# M3351 register map
File version: 1.0
Registers are 32-bit, read-write, reset 0x0 unless marked. A register's access mark holds for its fields unless they carry their own. Offsets are from the block's base; [hi:lo] are bit positions; {n}, {i} and the like mark numbered series; 'fields as' and 'values as' point back to an identical list.

## I3C0 (part 2 of 2) — I3C Register Map
Base 0x40086000
Same registers: I3C0_NS 0x50086000
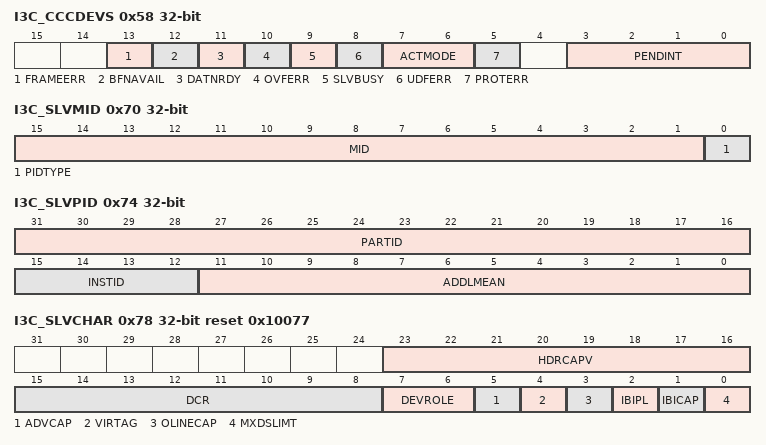
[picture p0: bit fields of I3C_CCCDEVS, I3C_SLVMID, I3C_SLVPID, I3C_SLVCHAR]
0x58 I3C_CCCDEVS ro — I3C Target Device Operating Status Register
  [13] FRAMEERR — Frame Error. This bit is set when private write request from Controller has frame error in HDR-DDR mode. Note: This bit is cleared only after Controller reads the device status through GETSTATUS CCC.
    0=Frame error did not occurred; 1=Frame error occurred
  [12] BFNAVAIL — Buffer Not Available. This bit is set when private write request from Controller is NACKED because of RX buffer not having RXSTATH (I3C_DBTHCTL[26:24]) number of empty locations or response buffer is full. Note: In SDR mode of operation, this bit is cleared when the Controller issues GETSTATUS CCC or upon space becoming available in the buffer and the successful completion of the next write transfer. Note: In HDR mode of operation, it is cleared only when Controller issues GETSTATUS CCC.
    0=Buffer Not Available did not occurred; 1=Buffer Not Available occurred
  [11] DATNRDY — Data Not Ready. This bit is set when private read request from Controller is NACKED because of any of the following conditions: Command FIFO Empty. Transmit FIFO threshold is not met. Response FIFO Full. Note: This bit is cleared when the Controller issues GETSTATUS CCC or upon successful completion of the subsequent read transfer.
    0=Data Not Ready did not occurred; 1=Data Not Ready occurred
  [10] OVFERR — Overflow Error. Overflow error condition detected during Controller write transfer. This bit is cleared only after Controller reads the device status through GETSTATUS CCC.
  [9] SLVBUSY — Target Busy. This bit is set if any change is made by the current Controller in to MRL register or occurance of any error. Note: This bit is cleared after Target application resumes the Target operation by writing RESUME bit (I3C_DEVCTL[30]) 1.
    0=Target not in Busy state; 1=Target in Busy state
  [8] UDFERR — Underflow Error. Underflow error condition detected during Controller read transfer. This bit is set if Target device terminates a read transfer because of unavailability of data in the transmit buffer. Note: This bit is cleared only after Controller reads the device status through GETSTATUS CCC.
    0=Underflow Error did not occurred; 1=Underflow Error occurred
  [7:6] ACTMODE — Activity Mode. This field is forced to be 0x0.
  [5] PROTERR — Protocol Error. This bit is set when the Target device encouters a Parity/CRC error during write data transfer. Note: This bit is cleared only after Controller reads the device status through GETSTATUS CCC.
    0=Protocol Error did not occurred; 1=Protocol Error occurred
  [3:0] PENDINT — Pending Interrupt. This field reflects the PENDINT (I3C_DEVCTL[6:3]) value.
0x70 I3C_SLVMID — I3C Target MIPI Manufacturer ID Register
  [15:1] MID — MIPI Manufacturer ID. This field reflects the PID[47:33]. (PID[47:0] Target Device 48-bit Provisioned ID)
  [0] PIDTYPE — Provisioned ID Type Selector. This bit reflects the PID[32]. (PID[47:0] Target Device 48-bit Provisioned ID)
    0=Vendor Fixed Value; 1=Random Value
0x74 I3C_SLVPID — I3C Target Provisional ID Register
  [31:16] PARTID — Part ID. This field reflects the PID[31:16]. (PID[47:0] Target Device 48-bit Provisioned ID)
  [15:12] INSTID — Instance ID. This field reflects the PID[15:12]. (PID[47:0] Target Device 48-bit Provisioned ID)
  [11:0] ADDLMEAN — Additional Meaning. This field reflects the PID[11:0]. (PID[47:0] Target Device 48-bit Provisioned ID)
0x78 I3C_SLVCHAR reset 0x10077 — I3C Target Characteristic Register
  [23:16] HDRCAPV — I3C Device HDR Capability Value. Forced to 0x1. Note: This field is read only.
  [15:8] DCR — I3C Device Characteristic Value. This field reflects the DCR[7:0] value.
  [7:6] DEVROLE — Device Role. This field reflects the BCR[7:6] and forced to 0x1. Note: This bit is read only.
  [5] ADVCAP — Advanced Capabilities. This bit reflects the BCR[5] value.
    0=Does not support optional advanced capabilities; 1=Supports optional advanced capabilities. Use GETCAPS CCC to determine which ones
  [4] VIRTAG — Virtual Target. This bit reflects the BCR[4] and forced to 0x1. Note: This bit is read only.
  [3] OLINECAP — Offline Capable. This bit reflects the BCR[3] and forced to 0x0. Note: This bit is read only.
  [2] IBIPL — IBI Payload. This bit reflects the BCR[2] and forced to 0x1. Note: This bit is read only.
  [1] IBICAP — IBI Request Capable. This bit reflects the BCR[1] and forced to 0x1. Note: This bit is read only.
  [0] MXDSLIMT — Max Data Speed Limitation. This bit reflects the BCR[0].
    0=No limitation; 1=Limitation
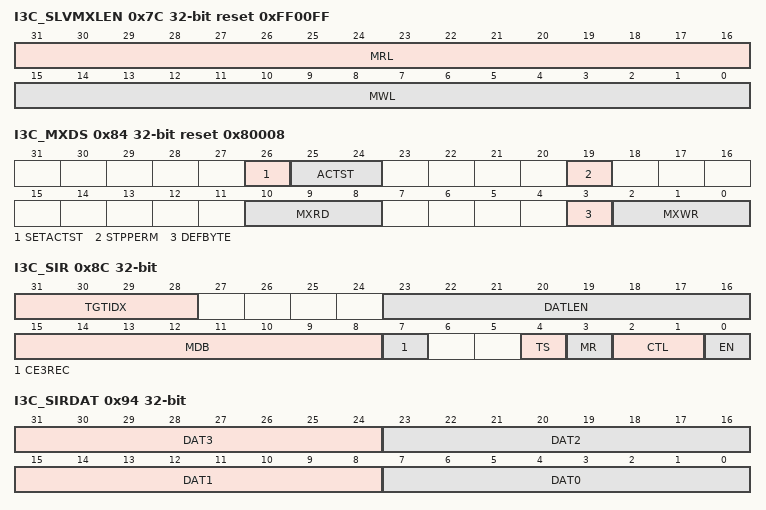
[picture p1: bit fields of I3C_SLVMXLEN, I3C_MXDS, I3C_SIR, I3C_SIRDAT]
0x7C I3C_SLVMXLEN ro reset 0xFF00FF — I3C Target Maximum Write/Read Length Register
  [31:16] MRL — I3C Device Max Read Length. This field reflects the maximum read length in Target mode. It only can be updated if SETMRL CCC is received. Note: This field is read only.
  [15:0] MWL — I3C Device Max Write Length. This field reflects the maximum write length in Target mode. It only can be updated if SETMWL CCC is received. Note: This field is read only.
0x84 I3C_MXDS reset 0x80008 — I3C Target Maximum Data Speed Register
  [26] SETACTST — Set Activity State. This bit indicates whether the Active Controller should set the Bus to the Activity State indicated in ACTST (I3C_MXDS[25:24]) before handing the Controller Role off to this I3C Device as part of the normal flow.
    0=The Target will not set the Bus to any Activity state; 1=The Target will set the Bus to any Activity state based on ACTST (I3C_MXDS[25:24])
  [25:24] ACTST — Active State. This 2-bit integer indicates whether this I3C device initially acts with a given Activity State, after becoming Active Controller on the Bus according to the Controller handoff flow.
  [19] STPPERM — Stop Permit. Specifies the STOP support between write and read.
    0=STOP after write will cancel the read; 1=Target permits the write and read to be seperated by a STOP
  [10:8] MXRD — Maximum Read Data Rate. Specifies the Maximum Sustained Data Rate for non-CCC messages sent by Target device to Controller device. Note: The 2nd byte which returned in the GETMXDS CCC.
  [3] DEFBYTE — Defining Byte support. Specifies the defining byte support of GETMXDS CCC.
    0=Defining byte is not supported for GETMXDS CCC; 1=Defining byte is supported for GETMXDS CCC
  [2:0] MXWR — Maximum Write Data Rate. Specifies the Maximum Sustained Data Rate for non-CCC messages sent by Controller device to Target device. Note: The 1st byte which returned in the GETMXDS CCC.
0x8C I3C_SIR — I3C Target Interrupt Request Control Register
  [31:28] TGTIDX — Target Index. This field should be programmed by the Target application to select from what Target the SIR is sent.
  [23:16] DATLEN — Target Interrupt Request Data Length. This field should be programmed by the Target application to give the data length for the payload data other than the MDB byte. This field is only applicable when BCR[2] (I3C_SLVCHAR[2] IBIPL) is set indicating that SIR supports payload data.
  [15:8] MDB — Mandatory Data Byte. This field gives the mandatory data byte which is required to be transmitted after the Controller ACK the Target address during SIR transfer. This field is only applicable when BCR[2] (I3C_SLVCHAR[2] IBIPL) is set indicating that SIR supports payload data.
  [7] CE3REC — CE3 Error Recovery. When the conditions for entering CE3 error are met (expiry of application running timer and I3C_SIR[0] (Target Interrupt Request) is not set to 0), the user will program this bit for recovering from CE3 error. Upon receiving this bit, the Target will move to Controller mode (update CTRACTS (I3C_PRESENTS[2] to 1) and generate a START (also clear the I3C_SIR[0]) and continue in generating 7E followed by STOP. Note: This bit is auto cleared by the Controller after the completion of recovery and moved to Controller mode.
    0=No effect; 1=Recovery from CE3 error
  [4] TS — Asynchronous Mode-0 Time Stamp. Enabling this bit will allow the Target to capture the Time-Stamp from external input signal during T_C1 (Target triggers START condition) and T_C2 (IBI is ACK by Controller) markers and append it along with the payload data.
    0=Time-Stamp payload data Disabled; 1=Time-Stamp payload data Enabled
  [3] MR — Controller Request. This bit is available only in the I3C Secondary Controller Configuration, and used for the Secondary Controller requests to be an Active Controller. Once issued and when the current Controller accepts (ACK) or if the Controller is unable to issue the MR, then the Controller clears this bit automatically and updates the IBISTS (I3C_SIRRESP[2:0]) field. If NACK response is received for the MR, the Controller reattempts the MR upon detecting the next START condition from the Controller or after the Bus Available Time.
    0=No effect; 1=Secondary Controller issues the MR on the I3C bus
  [2:1] CTL — Target Interrupt Request Control
    0=Indicates source of SIR data to be from the I3C_SIRDAT register; 1=Pull SDA line low and release SDA after sampling SCL low (pulled by Controller). Used for CE3 recovery during Controller Handover procedure
  [0] EN — Enable Target Interrupt Request. When set, the Target attempts to issue the SIR on the I3C bus based on CTL field. If CTL is set to 2'b00, Target clears this bit automatically and update the IBISTS field upon either current Controller accepts through generating (ACK) or If Target is unable to issue the SIR. If CTL is set to 2'b00, Target reattempts the SIR either upon detecting the next START condition from the Controller or after the Bus Available Time If NACK response is received for the SIR. If CTL is set to 2'b01, Target clears this bit automatically after sampling the SCL Low (pulled by Controller) for the generated SDA low. Target will release the SDA line upon sampling the SCL low. This feature is used in CE3 error recovery flow. Note: Once set, the application/software cannot clear this bit.
    0=No effect; 1=Send Target interrupt request
0x94 I3C_SIRDAT — I3C Target Interrupt Request Data Register
  [31:24] DAT3 — Data Byte 3. This register SIRDATA containing four bytes of SIR Data will be in effect only when SIR CTL (I3C_SIR[2:1]) is programmed to 0 provided the data length is up to 4. This field holds the fourth byte of SIR DATA that will be passed after the MDB when SIR is initiated by the application on writing into SIR EN (I3C_SIR[0]).
  [23:16] DAT2 — Data Byte 2. This register SIRDATA containing four bytes of SIR Data will be in effect only when SIR CTL (I3C_SIR[2:1]) is programmed to 0 provided the data length is up to 3. This field holds the third byte of SIR DATA that will be passed after the MDB when SIR is initiated by the application on writing into SIR EN (I3C_SIR[0]).
  [15:8] DAT1 — Data Byte 1. This register SIRDATA containing four bytes of SIR Data will be in effect only when SIR CTL (I3C_SIR[2:1]) is programmed to 0 provided the data length is up to 2. This field holds the second byte of SIR DATA that will be passed after the MDB when SIR is initiated by the application on writing into SIR EN (I3C_SIR[0]).
  [7:0] DAT0 — Data Byte 0. This register SIRDATA containing four bytes of SIR Data will be in effect only when SIR CTL (I3C_SIR[2:1]) is programmed to 0 provided the data length is up to 1. This field holds the first byte of SIR DATA that will be passed after the MDB when SIR is initiated by the application on writing into SIR EN (I3C_SIR[0]).
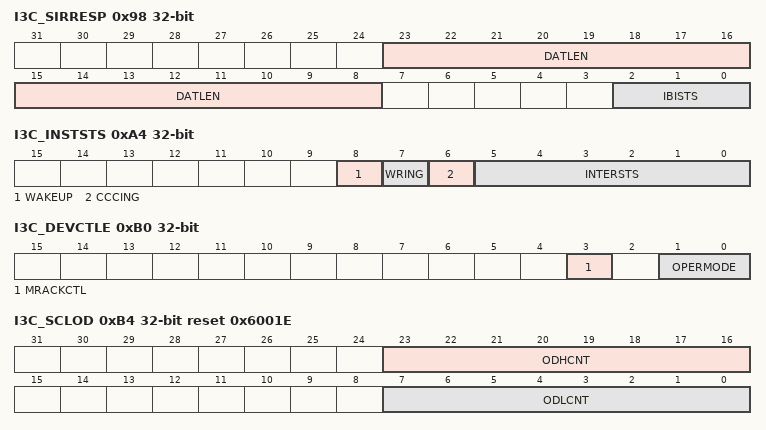
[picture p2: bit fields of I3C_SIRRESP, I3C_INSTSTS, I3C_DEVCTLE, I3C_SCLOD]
0x98 I3C_SIRRESP — I3C Target Interrupt Request Response Register
  [23:8] DATLEN — SIR Response Data Length. The value in this filed will indicate the number of bytes remaining that was not transmitted because of Controller early terminating the SIR transfer. In case the IBI is not attempted the number for bytes returned will be same as that programmed for IBI payload.
  [2:0] IBISTS — IBI Completion Status. This field is common for SIR and MR. Note: The Target does not attempt to issue the IBI and generates the IBI Completion Status as 3'b011 (IBI Not Attempted) if one of the following condition is true. The Controller has not assigned the Dynamic Address. The Controller has cleared the assigned Dynamic Address (through RSTDAA CCC). The Controller has disabled the IBI event (through DISEC CCC). The Controller has switched the role to Controller (applicable only for Secondary Controller Configuration). The Controller has NACKed the IBI request.
0xA4 I3C_INSTSTS ro — I3C Target Instant Status Register
  [8] WAKEUP — Target Wake-up Status. This bit indicates the Target is addressed and the application is required to be ready. Note 1: This bit is read only. Note 2: This bit is de-asserted after an address mismatch or on STOP. It is also de-asserted after a RE-START followed by 0x7E. This bit is synchronized from SCL domain to engine clock domain hence will have some synchronization latency associated with it.
    0=No address matched event; 1=An address match occurs indicating the Controller is trying to access this Target
  [7] WRING — Write Transfer On-going. This bit is asserted whenever there is an address match for the Controller Write transfer targeted for this Target. Note 1: This bit is read only. Note 2: This signal remains asserted until the write transfer is over from the Controller. This bit is synchronized from SCL domain to engine clock domain hence will have some synchronization latency associated with it.
    0=No write transfer operation; 1=Write transfer is on-going
  [6] CCCING — CCC Transfer On-going. Indicates a CCC transfer is on-going. This bit is asserted after 0x7E header the first bit of CCC is received and it is de-asserted either when a STOP or a 0x7E with a RE-START comes on the I3C line. Note 1: This bit is read only. Note 2: This bit is synchronized from SCL domain to engine clock domain hence will have some synchronization latency associated with it.
    0=No CCC transfer operation; 1=CCC transfer is on-going
  [5:0] INTERSTS — Target Internal Status. This field indicates the internal status of the Target. These bits indicates the internal status of the controller. Note: This field is read only.
0xB0 I3C_DEVCTLE — I3C Device Control Extended Register
  [3] MRACKCTL — ACK/NACK GETACCCR CCC. This bit is used in Target mode of operation. This bit serves as a Target (Secondare Controller) to ACK/NACK GETACCCR CCC from current Controller.
    0=ACK GETACCCR CCC; 1=NACK GETACCCR CCC
  [1:0] OPERMODE — Device Mode. This bit is used to select the Device Operation Mode before the device is enabled. Note 1: This field is written only when the I3C is disabled. Note 2: This field is automatically updated once the device role change happens in Secondary Controller mode.
    0=Controller; 1=Target
0xB4 I3C_SCLOD reset 0x6001E — I3C Controller Open Drain SCL Timing Register
  [23:16] ODHCNT — I3C Open Drain High Count. SCL Open-Drain High count for I3C transfers targeted to I3C Targets. Note: ODHCNT value can not be set 0 and minimum value is 5.
  [7:0] ODLCNT — I3C Open Drain Low Count. SCL Open-Drain Low count for I3C transfers targeted to I3C Targets. Note: ODLCNT value can not be set 0 and minimum value is 5.
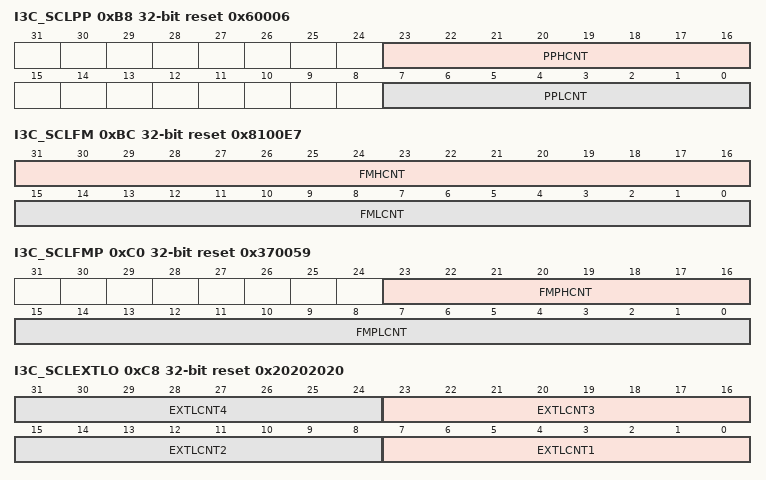
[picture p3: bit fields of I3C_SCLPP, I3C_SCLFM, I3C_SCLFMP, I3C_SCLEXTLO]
0xB8 I3C_SCLPP reset 0x60006 — I3C Controller Push Pull SCL Timing Register
  [23:16] PPHCNT — I3C Push Pull High Count. SCL Push-Pull High count for I3C transfers targeted to I3C Targets. Note: PPHCNT value can not be set 0 and minimum value is 5.
  [7:0] PPLCNT — I3C Push Pull Low Count. SCL Push-Pull Low count for I3C transfers targeted to I3C Targets. Note: PPLCNT value can not be set 0 and minimum value is 5.
0xBC I3C_SCLFM reset 0x8100E7 — I3C Controller I2C Fast Mode SCL Timing Register
  [31:16] FMHCNT — I2C Fast Mode High Count. SCL Open-Drain High count timing for I2C fast mode transfers. Note: FMHCNT value can not be set 0 and minimum value is 5.
  [15:0] FMLCNT — I2C Fast Mode Low Count. SCL Open-Drain Low count timing for I2C fast mode transfers. Note: FMLCNT value can not be set 0 and minimum value is 5.
0xC0 I3C_SCLFMP reset 0x370059 — I3C Controller I2C Fast Mode Plus SCL Timing Register
  [23:16] FMPHCNT — I2C Fast Mode Plus High Count. SCL Open-Drain High count timing for I2C fast mode plus transfers. Note: FMPHCNT value can not be set 0 and minimum value is 5.
  [15:0] FMPLCNT — I2C Fast Mode Plus Low Count. SCL Open-Drain Low count timing for I2C fast mode plus transfers. Note: FMPLCNT value can not be set 0 and minimum value is 5.
0xC8 I3C_SCLEXTLO reset 0x20202020 — I3C Controller SCL Extended Low Count Timing Register
  [8n-1:8n-8] EXTLCNT{n} (n=1..4) — I3C Extended Low Count {n}. This field is used for SDR{n} speed data transfer.
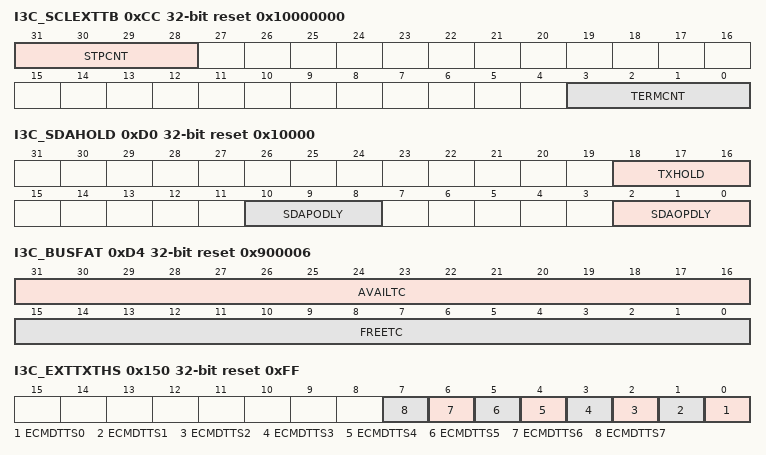
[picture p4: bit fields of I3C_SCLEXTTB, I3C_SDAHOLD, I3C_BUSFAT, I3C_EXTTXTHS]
0xCC I3C_SCLEXTTB reset 0x10000000 — I3C Controller SCL Extended Termination Bit Low Count Timing Register
  [31:28] STPCNT — STOP HOLD Count. Stop Hold Count in terms of ECLK which is used for generation of Stop Hold generation in Controller Mode.
  [3:0] TERMCNT — I3C Read Termination Bit Low Count. Extended I3C Read Termination Bit low count for I3C Read transfers. Effective Termination-Bit Low Period is derived based on the SDR speed mode as shown below: SDR0 speed: PPLCNT + TERMCNT. SDR1 speed: EXTLCNT1 + TERMCNT. SDR2 speed: EXTLCNT2 + TERMCNT. SDR3 speed: EXTLCNT3 + TERMCNT. SDR4 speed: EXTLCNT4 + TERMCNT. Note: The SDR0~4 speed mode is defined in SPEED field (Transfer Command Data Structure [23:21]).
0xD0 I3C_SDAHOLD reset 0x10000 — I3C Controller SDA Hold And Mode Switch Delay Timing Register
  [18:16] TXHOLD — Transmit Hold Time. This field is used to control the hold time of SDA during transmit mode in SDR DDR transfers. The valid values are 1 to 7. Others are Reserved. Note: Delay count unit is in terms of the core clock period.
  [10:8] SDAPODLY — SDA Push-Pull To Open-Drain Delay. The valid value are 0 to 4. Others are Reserved. Note: Delay count unit is in terms of the core clock period.
  [2:0] SDAOPDLY — SDA Open-Drain To Push-Pull Delay. The valid value are 0 to 4. Others are Reserved. Note: Delay count unit is in terms of the core clock period.
0xD4 I3C_BUSFAT reset 0x900006 — I3C Bus Free and Available Timing Register
  [31:16] AVAILTC — Target Bus Avaliable Time Count. This field is used in Target mode of operation. This field is used by the Target/Non-current Controller to initiate an IBI after STOP condition. Note: Bus Avaliable Time is used for issue In-Band Interrupt.
  [15:0] FREETC — Controller Bus Free Time Count. This field is used in Controller mode of operation. This field sets the Bus Free Time for initiating the transfer in Controller mode or generating IBI in non-current Controller mode. In Pure Bus System, this field represents tCAS parameter. In Mixed Bus system, this field is expected to be programmed to tLOW of I2C Timing.
0xD8 I3C_BUSIDLET reset 0x7080 — I3C Target Bus Idle Timing Register
  [19:0] IDLETC — Target Bus Idle Time Count. This field is used by the Target to initiate Hot-Join request if the Dynamic Address is not valid. Note: Bus Idle Time is used for issue Hot-Join request.
0xDC I3C_SCLLOWTO reset 0x3567E0 — I3C Controller SCL Low Timeout Register
  [25:0] LOWCNT — SCL Low Timeout Count. This count defines the number of engine clock periods (SCL Low duration) to count for generation of the SCL Low Bus Reset Pattern.
0xEC I3C_RELSDA reset 0x4E20 — I3C Target Release SDA Timing Register
  [19:0] RELSDATC — Release SDA Time Count. This field is used in the Target mode of operation to release the SDA upon detecting the SCL not toggling for the programmed time.
0xF4 I3C_BTDELY reset 0x400 — I3C HDR-BT Delay Byte Counter Register
  [10:0] DLYBCNT — HDR-BT Delay Byte Count. This field is used in Controller and Target mode to control the maximum delay bytes to be accommodated during HDR-BT read transfers. Functionality: In Controller Mode: Accepts delay bytes during HDR-BT read transfer and terminates the next transition control byte if the received delay bytes exceed the programmed value. In Target Mode: Utilizes this field to transmit delay bytes if required number of data bytes are insufficient to frame a HDR-BT Data block.
{0x130+4i} I3C_EXT{i}DAT wo (i=0..7) — I3C Target Mode Extended Command {i} Transfer Data Port Register
  [31:0] EXTDAT — Target Extended Command Transmit Data Port. This field is mapped to the EXTCMDx TX-Data Buffer. The transmit data should always be packed as 4-byte aligned data words and written to the EXTDAT. If the command length is not aligned to 4-bytes, then the additional bytes are ignored.
0x150 I3C_EXTTXTHS ro reset 0xFF — I3C Target Mode Extended Command Transmit Threshold Status Register
  [all] fields
    0=Number of empty locations in transmit buffer is less than TXEBTH setting; 1=Number of empty locations in transmit buffer is greater than or equal to TXEBTH setting
  [n] ECMDTTS{n} (n=0..7) — EXTCMD{n} Transmit Threshold Status. This bit is set when the number of empty locations in transmit buffer is greater than or equal to threshold value specified by by TXEBTH (I3C_EXTTHLD[18:16]) setting. This bit is cleared automatically when number of empty locations in transmit buffer is less than threshold value specified.
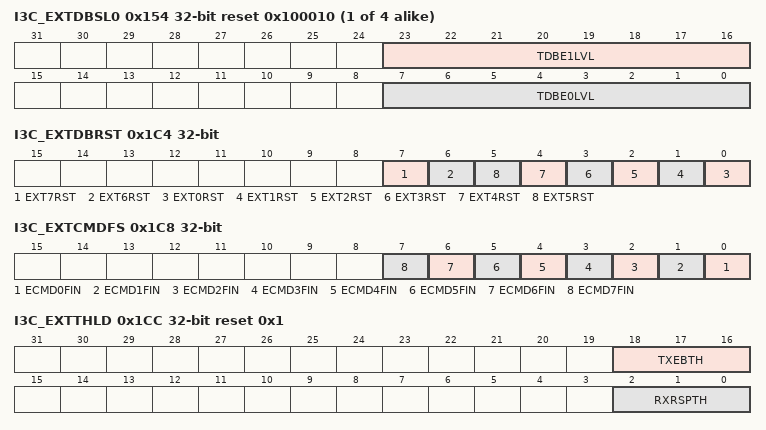
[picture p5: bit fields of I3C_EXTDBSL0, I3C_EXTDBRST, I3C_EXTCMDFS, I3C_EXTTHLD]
{0x154+4i} I3C_EXTDBSL{i} ro reset 0x100010 (i=0..3) — I3C Target Mode Extended Command Transmit Data Buffer Status Level Register {i}
  [23:16] TDBE{2i+1}LVL — EXT{2i+1}LVL Transmit Data Buffer Empty Level Value. Contains the number of empty locations in the EXT{2i+1}CMD transmit data buffer.
  [7:0] TDBE{2i}LVL — EXT{2i}LVL Transmit Data Buffer Empty Level Value. Contains the number of empty locations in the EXT{2i}CMD transmit data buffer.
{0x164+0xC*i} I3C_EXT{i}CMDW1 (i=0..7) — I3C Target Mode Extended Command {i} Word 1 Register
  [31:0] CMDWORD1 — Extended Transmit Command Word-1. This register represents Extended Command Word-1 used to push commands that enables the Target to respond with Data for either Private or Vendor-CCC Read command received from the Controller. Note: Refer to sub section 'Extended Transmit Command Data Structure' for more details.
{0x168+0xC*i} I3C_EXT{i}CMDW2 (i=0..7) — I3C Target Mode Extended Command {i} Word 2 Register
  [31:0] CMDWORD2 — Extended Transmit Command Word-2. This register represents Extended Command Word-2 used to push commands that enables the Target to respond with Data for either Private or Vendor-CCC Read command received from the Controller. Note: Refer to sub section 'Extended Transmit Command Data Structure' for more details.
{0x16C+0xC*i} I3C_EXT{i}CMDW3 (i=0..7) — I3C Target Mode Extended Command {i} Word 3 Register
  [31:0] CMDWORD3 — Extended Transmit Command Word-3. This register represents Extended Command Word-3 used to push commands that enables the Target to respond with Data for either Private or Vendor-CCC Read command received from the Controller. Note: Refer to sub section 'Extended Transmit Command Data Structure' for more details.
0x1C4 I3C_EXTDBRST — I3C Target Mode Extended Command Transmit Data Buffer Reset Register
  [7] EXT7RST — EXT7CMD Transmit Data Buffer Software Reset. Note: This bit is cleared automatically once the EXTCMD transmit data buffer reset is completed.
    0=No effect or transmit data buffer reset is completed; 1=Set 1 to exercise EXT7CMD transmit data buffer reset
  [6] EXT6RST — EXT6CMD Transmit Data Buffer Software Reset. Note: This bit is cleared automatically once the EXTCMD transmit data buffer reset is completed..
    0=No effect or transmit data buffer reset is completed; 1=Set 1 to exercise EXT6CMD transmit data buffer reset
  [n] EXT{n}RST (n=0..5) — EXT{n}CMD Transmit Data Buffer Software Reset. Note: This bit is cleared automatically once the EXTCMD transmit data buffer reset is completed.
    0=No effect or transmit data buffer reset is completed; 1=Set 1 to exercise EXT{n}CMD transmit data buffer reset
0x1C8 I3C_EXTCMDFS ro — I3C Target Mode Extended Command Finished Status Register
  [all] fields
    0=EXT0CMD no operation or not finished; 1=EXT0CMD has finished sending the Command
  [n] ECMD{n}FIN (n=0..7) — Extended Transmit Command {n} Finished Status. Note: This bit is read cleared automatically.
0x1CC I3C_EXTTHLD reset 0x1 — I3C Target Mode Extended Command Transmit and Receive Response Threshold Register
  [18:16] TXEBTH — Extended Transmit Empty Buffer Threshold. This field controls the number of empty locations (or above) in the Extended Transmit FIFO that trigger the EXTTXTH (I3C_INTSTS[21]) interrupt. The supported values for TXEBTH are:
  [2:0] RXRSPTH — Receive Data Response Generation Threshold
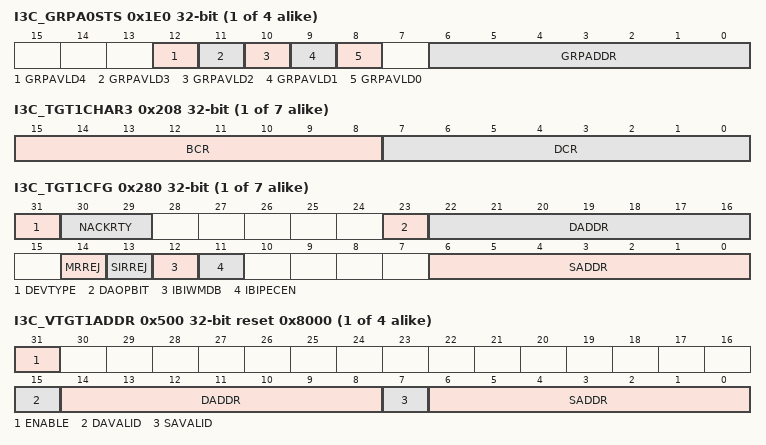
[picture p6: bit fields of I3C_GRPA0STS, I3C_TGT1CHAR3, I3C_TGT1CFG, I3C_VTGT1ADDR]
{0x1E0+4i} I3C_GRPA{i}STS (i=0..3) — I3C Target Mode Group Address {i} Status Register
  [12] GRPAVLD4 — Group Address Valid For Virtual Target 4. This bit is used to indicate whether the Group Address is valid or not for Virtual Target 4. Target mode sets this bit to 1 when Active Controller assigns the Group Address mentioned in GRPADDR field to Virtual Target 4 through SETGRPA CCC. Note 1: The bit will be set to 0 upon receiving RSTGRPA CCC. Note 2: Group Address 3 dose not support for Virtual Target 4.
    0=GRPADDR is invalid for Virtual Target 4; 1=GRPADDR is valid for Virtual Target 4
  [11] GRPAVLD3 — Group Address Valid For Virtual Target 3. This bit is used to indicate whether the Group Address is valid or not for Virtual Target 3. Target mode sets this bit to 1 when Active Controller assigns the Group Address mentioned in GRPADDR field to Virtual Target 3 through SETGRPA CCC. Note: The bit will be set to 0 upon receiving RSTGRPA CCC.
    0=GRPADDR is invalid for Virtual Target 3; 1=GRPADDR is valid for Virtual Target 3
  [10] GRPAVLD2 — Group Address Valid For Virtual Target 2. This bit is used to indicate whether the Group Address is valid or not for Virtual Target 2. Target mode sets this bit to 1 when Active Controller assigns the Group Address mentioned in GRPADDR field to Virtual Target 2 through SETGRPA CCC. Note: The bit will be set to 0 upon receiving RSTGRPA CCC.
    0=GRPADDR is invalid for Virtual Target 2; 1=GRPADDR is valid for Virtual Target 2
  [9] GRPAVLD1 — Group Address Valid For Virtual Target 1. This bit is used to indicate whether the Group Address is valid or not for Virtual Target 1. Target mode sets this bit to 1 when Active Controller assigns the Group Address mentioned in GRPADDR field to Virtual Target 1 through SETGRPA CCC. Note: The bit will be set to 0 upon receiving RSTGRPA CCC.
    0=GRPADDR is invalid for Virtual Target 1; 1=GRPADDR is valid for Virtual Target 1
  [8] GRPAVLD0 — Group Address Valid For Target. This bit is used to indicate whether the Group Address is valid or not for Target. Target mode sets this bit to 1 when Active Controller assigns the Group Address mentioned in GRPADDR field to Target through SETGRPA CCC. Note: The bit will be set to 0 upon receiving RSTGRPA CCC.
    0=GRPADDR is invalid for Target; 1=GRPADDR is valid for Target
  [6:0] GRPADDR — Target Group Address. This field is used to store the Group Address assigned by the Active Controller. The Active Controller assigns this Group Address through SETGRPA CCC. Target mode uses this Group Address to acknowledge the write transfers along with Dynamic Address. Note: This field is read only in Target mode of operation and programmable by the application in Secondary Controller Mode.
{0x1F0+0x10*i} I3C_TGT{i}CHAR1 ro reset not defined (i=1..7) — I3C Target Device {i} Characteristic 1 Register
  [31:0] PIDMSB — Device Characteristic 1. This field is used in Controller mode of operation. The MSB 32-bit value of Provisional ID. Note: This field is read only.
{0x1F4+0x10*i} I3C_TGT{i}CHAR2 ro reset not defined (i=1..7) — I3C Target Device {i} Characteristic 2 Register
  [15:0] PIDLSB — Device Characteristic 2. This field is used in Controller mode of operation. The LSB 16-bit value of Provisional ID. Note: This field is read only.
{0x1F8+0x10*i} I3C_TGT{i}CHAR3 ro reset not defined (i=1..7) — I3C Target Device {i} Characteristic 3 Register
  [15:8] BCR — Bus Characteristic Value. This field is used in Controller mode of operation. Note: This field is read only.
  [7:0] DCR — Device Characteristic Value. This field is used in Controller mode of operation. Note: This field is read only.
{0x1FC+0x10*i} I3C_TGT{i}CHAR4 ro reset not defined (i=1..7) — I3C Target Device {i} Characteristic 4 Register
  [7:0] DADDR — Device Dynamic Address Assigned. This field is used in Controller mode of operation. Device Dynamic Address assigned. Note: This field is read only.
{0x27C+4i} I3C_TGT{i}CFG reset not defined (i=1..7) — I3C Target Device {i} Configuration Register
  [31] DEVTYPE — Type Of Device. This bit is used to select the device type.
    0=I3C; 1=I2C
  [30:29] NACKRTY — NACK Retry Count. This field is used to set the Device NACK Retry count for the particular device. If the Device NACK's for the device address, the Controller automatically retries the same device until this count expires. If the Target does not ACK for the mentioned number of retries, then Controller generates an error response and move to the Halt state. This feature is used for Retry Model for the following features mentioned in the I3C Specification: Retry Model for Direct GET CCC Commands. The incoming SIR-IBI matches with the Target address initated by the Controller.
  [23] DAOPBIT — Odd Parity Of Dynamic Address. This bit is the odd parity of the 7-bit Dynamic address used for ENTDAA address assignment.
  [22:16] DADDR — Device Dynamic Address. This field indicates the 7-bit Dynamic Address to be assigned for the winning I3C device when using ENTDAA command.
  [14] MRREJ — Controller Request Reject. In-Band Controller Request Reject bit is used to control, per device, whether to accept Controller Request from devices.
    0=Accept: ACK the Controller Request; 1=Reject: NACK the Controller Request and send auto DISEC CCC
  [13] SIRREJ — Target Interrupt Request Reject. In-Band Target Interrupt Request Reject bit is used to control, per device, whether to accept Target Interrupt Request from devices.
    0=Accept: ACK the SIR; 1=Reject: NACK the SIR and send auto DISEC CCC
  [12] IBIWMDB — IBI with Mandatory Byte. Mandatory one or more data bytes follow the accepted IBI from the device. Data byte continuation is indicated by T-Bit.
    0=IBI without Mandatory Byte; 1=IBI with one or more Mandatory Bytes
  [11] IBIPECEN — IBI with Packet Error Check. This bit controls whether Packet Error Check should be performed for IBI data from device. PEC byte is appended at the end of IBI data from the device. This bit also controls whether PEC byte has to be send for auto disable CCC when controller NACKs the IBI.
    0=Packet Error Check Disabled for IBI; 1=Packet Error Check Enabled for IBI
  [6:0] SADDR — Device Static Address. This field indicates the 7-bit Static Address for the I2C device.
{0x4E0+0x20*i} I3C_VTGT{i}ADDR reset 0x8000 (i=1..4) — I3C Virtual Target {i} Address Register
  [31] ENABLE — Virtual Target Enable Bit. Note: The Virtual Target should only be enabled/disabled when the Target is disabled (I3C_DEVCTL[31] 0).
    0=Disable the specified Virtual Target; 1=Enable the specified Virtual Target
  [15] DAVALID — Virtual Target Dynamic Address Valid Bit. This bit is reflect whether the Virtual Target DADDR is valid or not. In Target Mode of operation, this bit will be set to 1 when active Controller assigns the Virtual Target Dynamic Address during Address Assignment Mechanism. Note: This bit can be auto-clear to 0 if RSTDAA CCC is reveived.
    0=Virtual Target Dynamic Address is invalid; 1=Virtual Target Dynamic Address is valid
  [14:8] DADDR — Virtual Target Dynamic Address. This field is used to reflect the Virtual Target Dynamic Address. The active Controller can use this address for I3C transfers. The active Controller assigns this Dynamic Address through Address Assignment Mechanism. (ENTDAA , SETDASA, SETAASA or SETNEWDA CCC).
  [7] SAVALID — Virtual Target Static Address Valid Bit
    0=Virtual Target Static Address is invalid; 1=Virtual Target Static Address is valid
  [6:0] SADDR — Virtual Target Static Address. Target uses this address to respond to SETDASA CCC Command to get the Virtuel Target Dynamic Address or Legacy I2C Read/Write operation if Virtual Target Static Address is valid.
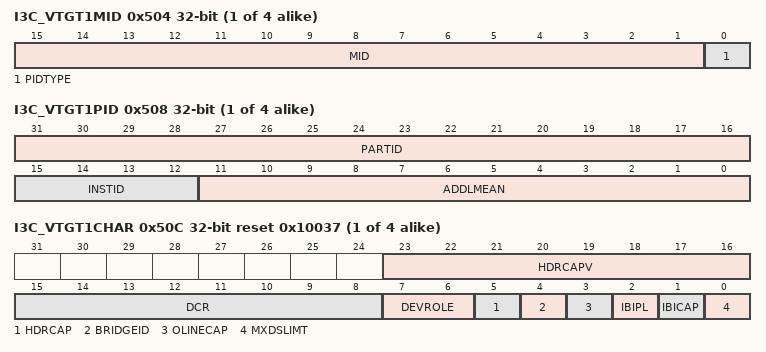
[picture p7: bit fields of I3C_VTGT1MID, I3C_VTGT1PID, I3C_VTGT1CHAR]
{0x4E4+0x20*i} I3C_VTGT{i}MID (i=1..4) — I3C Virtua Target {i} Manufacturer ID Register
  [15:1] MID — Virtual Target MIPI Manufacturer ID. This field reflects the PID[47:33]. (PID[47:0] Target Device 48-bit Provisioned ID)
  [0] PIDTYPE — Virtual Target Provisioned ID Type Selector. This bit reflects the PID[32]. (PID[47:0] Target Device 48-bit Provisioned ID)
    0=Vendor Fixed Value; 1=Random Value
{0x4E8+0x20*i} I3C_VTGT{i}PID (i=1..4) — I3C Virtual Target {i} Provisional ID Register
  fields as I3C_SLVPID
{0x4EC+0x20*i} I3C_VTGT{i}CHAR ro reset 0x10037 (i=1..4) — I3C Virtual Target {i} Characteristic Register
  [23:16] HDRCAPV — I3C Device HDR Capability Value. Forced to 1. Note: This field is read only.
  [15:8] DCR — I3C Device Characteristic Value. This field reflects the DCR[7:0] value.
  [7:6] DEVROLE — Device Role. This field reflects the BCR[7:6] and forced to 0x0. Note: This bit is read only.
  [5] HDRCAP — HDR Capable. This bit reflects the BCR[5] value.
    0=SDR only; 1=SDR and HDR capable
  [4] BRIDGEID — Bridge Identifier. This bit reflects the BCR[4] and forced to 0x1. Note: This bit is read only.
  [3] OLINECAP — Offline Capable. This bit reflects the BCR[3] and forced to 0x0. Note: This bit is read only.
  [2] IBIPL — IBI Payload. This bit reflects the BCR[2] and forced to 0x1. Note: This bit is read only.
  [1] IBICAP — IBI Request Capable. This bit reflects the BCR[1] and forced to 0x1. Note: This bit is read only.
  [0] MXDSLIMT — Max Data Speed Limitation. This bit reflects the BCR[0]. Target returns the MXWR (I3C_MXDS[2:0]) and MXRD (I3C_MXDS[10:8]) in response the GETMXDS CCC sent by Controller.
    0=No limitation; 1=Limitation
